# PIC18LF4550 register map
Vendor: Microchip
Architecture 18xxxx. Special function registers and configuration words.
Registers are 8-bit, read-write, reset 0x0 unless marked. A register's access mark holds for its fields unless they carry their own. Addresses are absolute, and some are shared; only a register's first bit layout is shown; lines under a group give offsets from that group; [hi:lo] are bit positions; {n}, {i} and the like mark numbered series; 'fields as' and 'values as' point back to an identical list; <NAME> marks a mode.

## Further device data
pins=1: MCLR/Vpp/RE3; 2: RA0/AN0; 3: RA1/AN1; 4: RA2/AN2/Vref-/Cvref; 5: RA3/AN3/Vref+; 6: RA4/T0CKI/C1OUT/RCV; 7: RA5/AN4/SS/HLVDIN/C2OUT; 8: RE0/AN5/CK1SPP; 9: RE1/AN6/CK2SPP; 10: RE2/AN7/OESPP; 11: Vdd; 12: Vss; 13: OSC1/CLKI; 14: OSC2/CLKO/RA6; 15: RC0/T1OSO/T13CKI; 16: RC1/T1OSI/CCP2/UOE; 17: RC2/CCP1/P1A; 18: Vusb; 19: RD0/SPP0; 20: RD1/SPP1; 21: RD2/SPP2; 22: RD3/SPP3; 23: RC4/D-/VM; 24: RC5/D+/VP; 25: RC6/TX/CK; 26: RC7/RX/DT/SDO; 27: RD4/SPP4; 28: RD5/SPP5/P1B; 29: RD6/SPP6/P1C; 30: RD7/SPP7/P1D; 31: Vss; 32: Vdd; 33: RB0/AN12/INT0/FLT0/SDI/SDA; 34: RB1/AN10/INT1/SCK/SCL; 35: RB2/AN8/INT2/VMO; 36: RB3/AN9/CCP2/VPO; 37: RB4/AN11/KBI0/CSSPP; 38: RB5/KBI1/PGM; 39: RB6/KBI2/PGC; 40: RB7/KBI3/PGD

## CONFIG — Configuration words, addresses in ProgramSpace
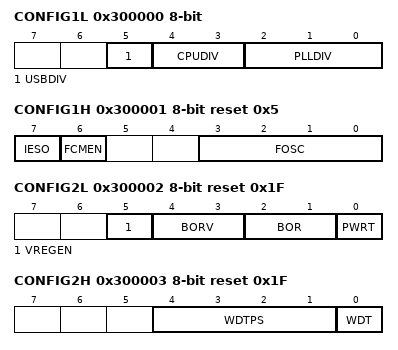
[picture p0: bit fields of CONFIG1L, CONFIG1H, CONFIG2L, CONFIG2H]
0x300000 CONFIG1L
  [5] USBDIV — USB Clock Selection bit (used in Full-Speed USB mode only; UCFG:FSEN = 1)
    1=USB clock source comes from the 96 MHz PLL divided by 2; 0=USB clock source comes directly from the primary oscillator block with no postscale
  [4:3] CPUDIV — System Clock Postscaler Selection bits
    3=OSC4_PLL6 ([Primary Oscillator Src: /4][96 MHz PLL Src: /6]); 2=OSC3_PLL4 ([Primary Oscillator Src: /3][96 MHz PLL Src: /4]); 1=OSC2_PLL3 ([Primary Oscillator Src: /2][96 MHz PLL Src: /3]); 0=OSC1_PLL2 ([Primary Oscillator Src: /1][96 MHz PLL Src: /2])
  [2:0] PLLDIV — PLL Prescaler Selection bits
    7=Divide by 12 (48 MHz oscillator input); 6=Divide by 10 (40 MHz oscillator input); 5=Divide by 6 (24 MHz oscillator input); 4=Divide by 5 (20 MHz oscillator input); 3=Divide by 4 (16 MHz oscillator input); 2=Divide by 3 (12 MHz oscillator input); 1=Divide by 2 (8 MHz oscillator input); 0=No prescale (4 MHz oscillator input drives PLL directly)
0x300001 CONFIG1H reset 0x5
  [7] IESO — Internal/External Oscillator Switchover bit
    1=ON (Oscillator Switchover mode enabled); 0=OFF (Oscillator Switchover mode disabled)
  [6] FCMEN — Fail-Safe Clock Monitor Enable bit
    1=ON (Fail-Safe Clock Monitor enabled); 0=OFF (Fail-Safe Clock Monitor disabled)
  [3:0] FOSC — Oscillator Selection bits
    0b111x=HSPLL_HS (HS oscillator, PLL enabled (HSPLL)); 0b110x=HS (HS oscillator (HS)); 11=INTOSC_HS (Internal oscillator, HS oscillator used by USB (INTHS)); 10=INTOSC_XT (Internal oscillator, XT used by USB (INTXT)); 9=INTOSC_EC (Internal oscillator, CLKO function on RA6, EC used by USB (INTCKO)); 8=INTOSCIO_EC (Internal oscillator, port function on RA6, EC used by USB (INTIO)); 7=ECPLL_EC (EC oscillator, PLL enabled, CLKO function on RA6 (ECPLL)); 6=ECPLLIO_EC (EC oscillator, PLL enabled, port function on RA6 (ECPIO)); 5=EC_EC (EC oscillator, CLKO function on RA6 (EC)); 4=ECIO_EC (EC oscillator, port function on RA6 (ECIO)); 0b001x=XTPLL_XT (XT oscillator, PLL enabled (XTPLL)); 0b000x=XT_XT (XT oscillator (XT))
0x300002 CONFIG2L reset 0x1F
  [5] VREGEN — USB Voltage Regulator Enable bit
    1=ON (USB voltage regulator enabled); 0=OFF (USB voltage regulator disabled)
  [4:3] BORV — Brown-out Reset Voltage bits
    3=Minimum setting; 2=2; 1=1; 0=Maximum setting
  [2:1] BOR — Brown-out Reset Enable bits
    3=ON (Brown-out Reset enabled in hardware only (SBOREN is disabled)); 2=ON_ACTIVE (Brown-out Reset enabled in hardware only and disabled in Sleep mode (SBOREN is disabled)); 1=SOFT (Brown-out Reset enabled and controlled by software (SBOREN is enabled)); 0=OFF (Brown-out Reset disabled in hardware and software)
  [0] PWRT — Power-up Timer Enable bit
    1=OFF (PWRT disabled); 0=ON (PWRT enabled)
0x300003 CONFIG2H reset 0x1F
  [4:1] WDTPS — Watchdog Timer Postscale Select bits
    15=1:32768; 14=1:16384; 13=1:8192; 12=1:4096; 11=1:2048; 10=1:1024; 9=1:512; 8=1:256; 7=1:128; 6=1:64; 5=1:32; 4=1:16; 3=1:8; 2=1:4; 1=1:2; 0=1:1
  [0] WDT — Watchdog Timer Enable bit
    1=ON (WDT enabled); 0=OFF (WDT disabled (control is placed on the SWDTEN bit))
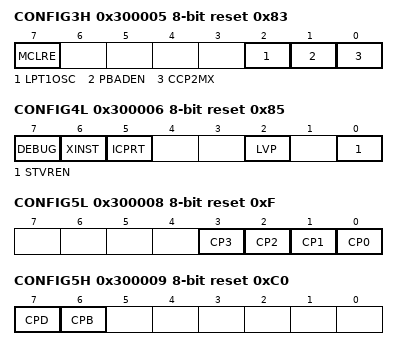
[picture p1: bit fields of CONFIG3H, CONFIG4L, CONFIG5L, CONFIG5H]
0x300005 CONFIG3H reset 0x83
  [7] MCLRE — MCLR Pin Enable bit
    1=ON (MCLR pin enabled; RE3 input pin disabled); 0=OFF (RE3 input pin enabled; MCLR pin disabled)
  [2] LPT1OSC — Low-Power Timer 1 Oscillator Enable bit
    1=ON (Timer1 configured for low-power operation); 0=OFF (Timer1 configured for higher power operation)
  [1] PBADEN — PORTB A/D Enable bit
    1=ON (PORTB<4:0> pins are configured as analog input channels on Reset); 0=OFF (PORTB<4:0> pins are configured as digital I/O on Reset)
  [0] CCP2MX — CCP2 MUX bit
    1=ON (CCP2 input/output is multiplexed with RC1); 0=OFF (CCP2 input/output is multiplexed with RB3)
0x300006 CONFIG4L reset 0x85
  [7] DEBUG — Background Debugger Enable bit
    1=OFF (Background debugger disabled, RB6 and RB7 configured as general purpose I/O pins); 0=ON (Background debugger enabled, RB6 and RB7 are dedicated to In-Circuit Debug)
  [6] XINST — Extended Instruction Set Enable bit
    1=ON (Instruction set extension and Indexed Addressing mode enabled); 0=OFF (Instruction set extension and Indexed Addressing mode disabled (Legacy mode))
  [5] ICPRT — Dedicated In-Circuit Debug/Programming Port (ICPORT) Enable bit
    1=ON (ICPORT enabled); 0=OFF (ICPORT disabled)
  [2] LVP — Single-Supply ICSP Enable bit
    1=ON (Single-Supply ICSP enabled); 0=OFF (Single-Supply ICSP disabled)
  [0] STVREN — Stack Full/Underflow Reset Enable bit
    1=ON (Stack full/underflow will cause Reset); 0=OFF (Stack full/underflow will not cause Reset)
0x300008 CONFIG5L reset 0xF
  [3] CP3 — Code Protection bit
    1=OFF (Block 3 (006000-007FFFh) is not code-protected); 0=ON (Block 3 (006000-007FFFh) is code-protected)
  [2] CP2 — Code Protection bit
    1=OFF (Block 2 (004000-005FFFh) is not code-protected); 0=ON (Block 2 (004000-005FFFh) is code-protected)
  [1] CP1 — Code Protection bit
    1=OFF (Block 1 (002000-003FFFh) is not code-protected); 0=ON (Block 1 (002000-003FFFh) is code-protected)
  [0] CP0 — Code Protection bit
    1=OFF (Block 0 (000800-001FFFh) is not code-protected); 0=ON (Block 0 (000800-001FFFh) is code-protected)
0x300009 CONFIG5H reset 0xC0
  [7] CPD — Data EEPROM Code Protection bit
    1=OFF (Data EEPROM is not code-protected); 0=ON (Data EEPROM is code-protected)
  [6] CPB — Boot Block Code Protection bit
    1=OFF (Boot block (000000-0007FFh) is not code-protected); 0=ON (Boot block (000000-0007FFh) is code-protected)
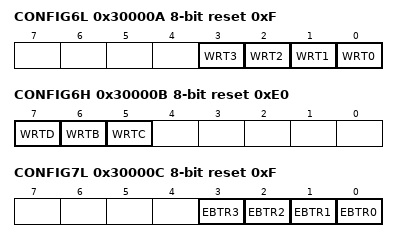
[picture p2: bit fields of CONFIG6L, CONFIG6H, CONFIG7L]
0x30000A CONFIG6L reset 0xF
  [3] WRT3 — Write Protection bit
    1=OFF (Block 3 (006000-007FFFh) is not write-protected); 0=ON (Block 3 (006000-007FFFh) is write-protected)
  [2] WRT2 — Write Protection bit
    1=OFF (Block 2 (004000-005FFFh) is not write-protected); 0=ON (Block 2 (004000-005FFFh) is write-protected)
  [1] WRT1 — Write Protection bit
    1=OFF (Block 1 (002000-003FFFh) is not write-protected); 0=ON (Block 1 (002000-003FFFh) is write-protected)
  [0] WRT0 — Write Protection bit
    1=OFF (Block 0 (000800-001FFFh) is not write-protected); 0=ON (Block 0 (000800-001FFFh) is write-protected)
0x30000B CONFIG6H reset 0xE0
  [7] WRTD — Data EEPROM Write Protection bit
    1=OFF (Data EEPROM is not write-protected); 0=ON (Data EEPROM is write-protected)
  [6] WRTB — Boot Block Write Protection bit
    1=OFF (Boot block (000000-0007FFh) is not write-protected); 0=ON (Boot block (000000-0007FFh) is write-protected)
  [5] WRTC — Configuration Register Write Protection bit
    1=OFF (Configuration registers (300000-3000FFh) are not write-protected); 0=ON (Configuration registers (300000-3000FFh) are write-protected)
0x30000C CONFIG7L reset 0xF
  [3] EBTR3 — Table Read Protection bit
    1=OFF (Block 3 (006000-007FFFh) is not protected from table reads executed in other blocks); 0=ON (Block 3 (006000-007FFFh) is protected from table reads executed in other blocks)
  [2] EBTR2 — Table Read Protection bit
    1=OFF (Block 2 (004000-005FFFh) is not protected from table reads executed in other blocks); 0=ON (Block 2 (004000-005FFFh) is protected from table reads executed in other blocks)
  [1] EBTR1 — Table Read Protection bit
    1=OFF (Block 1 (002000-003FFFh) is not protected from table reads executed in other blocks); 0=ON (Block 1 (002000-003FFFh) is protected from table reads executed in other blocks)
  [0] EBTR0 — Table Read Protection bit
    1=OFF (Block 0 (000800-001FFFh) is not protected from table reads executed in other blocks); 0=ON (Block 0 (000800-001FFFh) is protected from table reads executed in other blocks)
0x30000D CONFIG7H reset 0x40
  [6] EBTRB — Boot Block Table Read Protection bit
    1=OFF (Boot block (000000-0007FFh) is not protected from table reads executed in other blocks); 0=ON (Boot block (000000-0007FFh) is protected from table reads executed in other blocks)
